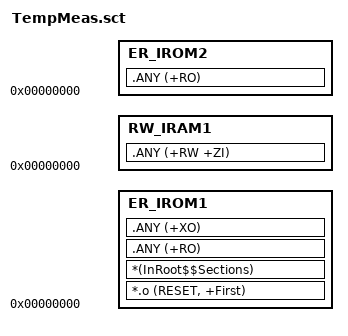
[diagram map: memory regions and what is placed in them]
; ******************************************************************
; *** Scatter-Loading Description File generated by Embedded IDE ***
; ******************************************************************

LR_IROM1 0x0000000000 0x0000000000 {
	ER_IROM1 0x0000000000 0x0000000000 {
		*.o (RESET, +First) 
		*(InRoot$$Sections) 
		.ANY (+RO) 
		.ANY (+XO) 
	}
	RW_IRAM1 0x00000000 0x00000000 {
		.ANY (+RW +ZI) 
	}
}

LR_IROM2 0x00000000 0x00000000 {
	ER_IROM2 0x00000000 0x00000000 {
		.ANY (+RO) 
	}
}

